# RL6955_IP_SVD register map
Vendor: Realtek
Registers are 32-bit, read-write, reset 0x0 unless marked. A register's access mark holds for its fields unless they carry their own. Offsets are from the block's base; [hi:lo] are bit positions; {n}, {i} and the like mark numbered series.

## WLAFE_REG
Base 0x40801480
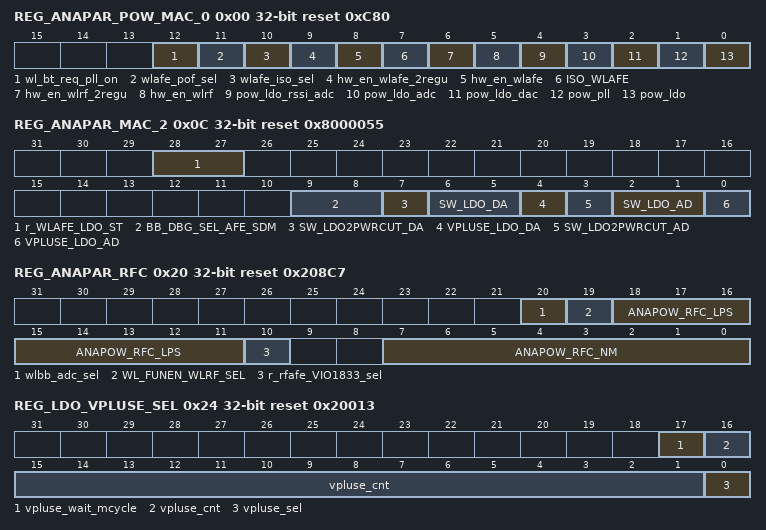
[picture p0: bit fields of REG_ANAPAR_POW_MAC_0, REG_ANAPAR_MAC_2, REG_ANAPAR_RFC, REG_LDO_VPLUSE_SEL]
0x00 REG_ANAPAR_POW_MAC_0 reset 0xC80
  [12] wl_bt_req_pll_on — 1:enable pll 320m
  [11] wlafe_pof_sel — Option to power off WLAFE 1: enable ,power off wlafe when bt&wl request off 0: disable ,keep wlafe power on when bt&wl request off
  [10] wlafe_iso_sel — Option to enable isolation of wlafe when power off WLAFE 1: enable ,0x00[7]will be written 1 when wlafe power off 0: disable ,0x00[7]will keep 0 when wlafe power off hw tie1 in RL6955
  [9] hw_en_wlafe_2regu — control 3.3V power reset of wl afe, need level shift to 3.3V by regu no use in RL6955
  [8] hw_en_wlafe — core power reset of wl afe no use in RL6955
  [7] ISO_WLAFE — isolation signal
  [6] hw_en_wlrf_2regu — control 3.3V power reset of wl rf, need level shift to 3.3V by regu
  [5] hw_en_wlrf — core power reset of wl rf
  [4] pow_ldo_rssi_adc — Power on ldo for rssi adc
  [3] pow_ldo_adc — Power on ldo for adc
  [2] pow_ldo_dac — Power on ldo for dac
  [1] pow_pll — Power on pll
  [0] pow_ldo — Power on AFE power cut and pll ldo
0x0C REG_ANAPAR_MAC_2 reset 0x8000055
  [28:27] r_WLAFE_LDO_ST — stable time select for WLAFE LDO 2'b00:10us, 2'b01:20us, 2'b10:100us, 2'b11:200us
  [9:8] BB_DBG_SEL_AFE_SDM — SDM debug selection
  [7] SW_LDO2PWRCUT_DA — 1 power cut mode 0 ldo mode (DA LDO)
  [6:5] SW_LDO_DA — Ldo voltage 00/01/10/11: 0.875V/0.9V/0.95V/1V (DAC LDO)
  [4] VPLUSE_LDO_DA — For DAC(WL DAC LDO)
  [3] SW_LDO2PWRCUT_AD — 1 power cut mode 0 ldo mode (AD LDO)
  [2:1] SW_LDO_AD — Ldo voltage 00/01/10/11: 0.875V/0.9V/0.95V/1V (ADC LDO)
  [0] VPLUSE_LDO_AD — For ADC(WL ADC LDO)
0x10 REG_DBG_WLAFE_PMC ro
  [31:0] dbg_wlafe_pmc — debug signal of wlafe_pmc [31]:pmc_rdy [30]:powon_req [29]:powoff_ref [28]:wlafe_is_power_on [27]:first_pon_flag [26]:pmc_timer_en [25]:|pmc_wem [24]:|pmc_wd [23:18]:0 [17]syspll_rdy [16]:wlafe_en_osc4m [15]:pmc_wr [14]:pmc_timer_out [13]:pmc_wr_done [12]:wl_power_flag [11]:bt_power_flag [10]:wl_pon_gnt [9]:bt_pon_gnt [8]:wlbt_pll_rdy [7]:en_xtal_frv_afe [6:0]pmc_state
0x14 REG_DBG_WLAFE ro
  [15:0] dbg_wlafe_reg — debug signal of wlafe_reg
0x18 REG_DUMMY
  [31:0] dummy — HW used only , these are for reserved.
0x20 REG_ANAPAR_RFC reset 0x208C7
  [20] wlbb_adc_sel — 1:if gnt bt is high,send 0x200 to wlbb as adc data 0:send adc data form afe out directly to wlbb
  [19] WL_FUNEN_WLRF_SEL — 1: select ANAPOW_RFC_NM as ANAPAR_RFC[7:0],used when RFAFE is active 0: select ANAPOW_RFC_LPS as ANAPAR_RFC[7:0],,used when RFAFE is power off
  [18:11] ANAPOW_RFC_LPS — wlan power rf control
  [10] r_rfafe_VIO1833_sel — IND_VIO1833 output decided by: 1: 1.8V 0: 3.3V
  [7:0] ANAPOW_RFC_NM — wlan power rf control
0x24 REG_LDO_VPLUSE_SEL reset 0x20013
  [17] vpluse_wait_mcycle — 1: vpluse_ldo_dac and vpluse_ldo_adc pull low should wait more cycle after ldo pull high
  [16:1] vpluse_cnt — vpluse_ldo high output delay cycle after pll_ldo set high,default:3(1.5us)
  [0] vpluse_sel — vpluse_ldo output decided by: 1: power on ldo 0: ctrl reg
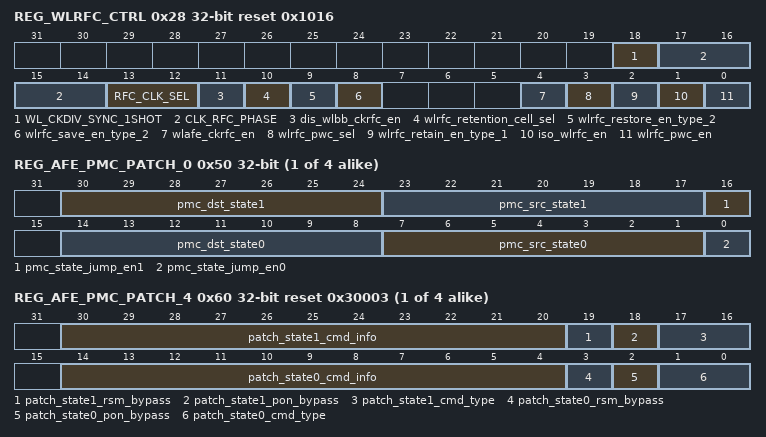
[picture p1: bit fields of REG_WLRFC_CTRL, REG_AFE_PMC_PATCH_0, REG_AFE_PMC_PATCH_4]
0x28 REG_WLRFC_CTRL access per field reset 0x1016
  [18] WL_CKDIV_SYNC_1SHOT rw — 1: sync 40M/80M clock phase with PLL
  [17:14] CLK_RFC_PHASE rw — 80M WLRFC clock phase control
  [13:12] RFC_CLK_SEL rw — 11/10:40M 01:80M 00:160M
  [11] dis_wlbb_ckrfc_en rw — the gating control of rfc clk is pta_ckrfc_en|wlbb_ckrfc_en|wlafe_ckrfc_en,and wlbb_ckrfc_en can not be control by register directly in RL6678,add option for top to control wlbb_ckrfc_en 1: disable wlbb_ckrfc_en; 0: enable wlbb_ckrfc_en
  [10] wlrfc_retention_cell_sel rw — 1:choose retention cell type I(U22 ULP),which is controlled by 0x28[2] 0:choose retention cell type II(RTKM),which is controlled by 0x28[9:8]
  [9] wlrfc_restore_en_type_2 wo — enable restoring value of retention DFF when wlmac power on,should be assert when reset is high
  [8] wlrfc_save_en_type_2 wo — enable saving value of retention DFF when wlmac power off or pg,should be assert when reset is high
  [4] wlafe_ckrfc_en rw — 1: enable WLRFC clock; 0: gated
  [3] wlrfc_pwc_sel rw — Option to turn off wlrfc pwr cut 1: enable 0: disable RL6955: RFC without retention FF. default is 0
  [2] wlrfc_retain_en_type_1 rw — 1 to 0:gen req to restore register in power on flow 0 to 1:gen req to backup register in power on flow default should be 1,otherwise there be unexpected leakage power when VCC is power off and VCCG is still on
  [1] iso_wlrfc_en rw — Isolation control for wlan rfc 1: isolation 0: attach
  [0] wlrfc_pwc_en rw — 1: gen request of wlan rfc power cut 0: gen request of turn off wlan rfc power cut
{0x50+4i} REG_AFE_PMC_PATCH_{i} (i=0..3)
  [30:24] pmc_dst_state{2i+1} — destination pmc state{2i+1} for state jump
  [23:17] pmc_src_state{2i+1} — source pmc state{2i+1} for state jump
  [16] pmc_state_jump_en{2i+1} — 1: when current afe pmc state hit pmc_src_state{2i+1}, next pmc state will jump to pmc_dst_state{2i+1}; 0:afe pmc follow old flow
  [14:8] pmc_dst_state{2i} — destination pmc state{2i} for state jump
  [7:1] pmc_src_state{2i} — source pmc state{2i} for state jump
  [0] pmc_state_jump_en{2i} — 1: when current afe pmc state hit pmc_src_state{2i}, next pmc state will jump to pmc_dst_state{2i}; 0:afe pmc follow old flow
{0x50+4i} REG_AFE_PMC_PATCH_{i} reset 0x30003 (i=4..7)
  [30:20] patch_state{2i-7}_cmd_info — *for write command: [30]:write value [29:25]:write address bit select [24:20]: write address dword select *for delay command: [30:20]: delay time, unit is 1 cycle *for poll command: [25]:poll value [24:20]: poll address bit select,poll 0x10 *for jump command: do nothing
  [19] patch_state{2i-7}_rsm_bypass — bypass the state command for resume flow
  [18] patch_state{2i-7}_pon_bypass — bypass the state command for pon flow
  [17:16] patch_state{2i-7}_cmd_type — 2'b00: write command; 2'b01:delay command; 2'b10:poll command;2'b11:jump to next state
  [14:4] patch_state{2i-8}_cmd_info — *for write command: [14]:write value [13:9]:write address bit select [8:4]: write address dword select *for delay command: [14:4]: delay time, unit is 1 cycle *for poll command: [9]:poll value [8:4]: poll address bit select,poll 0x10 *for jump command: do nothing
  [3] patch_state{2i-8}_rsm_bypass — bypass the state command for resume flow
  [2] patch_state{2i-8}_pon_bypass — bypass the state command for pon flow
  [1:0] patch_state{2i-8}_cmd_type — 2'b00: write command; 2'b01:delay command; 2'b10:poll command;2'b11:jump to next state
